# DECODER0_PVDEC_PIXEL register map
Vendor: Texas Instruments
Peripheral module from a debugger description file (folder J7ES).
Registers are 32-bit, read-write, reset 0x0 unless marked. A register's access mark holds for its fields unless they carry their own. Offsets are as the file gives them; lines under a group give offsets from that group; [hi:lo] are bit positions; {n}, {i} and the like mark numbered series; 'fields as' and 'values as' point back to an identical list; <NAME> marks a mode.

## DECODER0_PVDEC_PIXEL
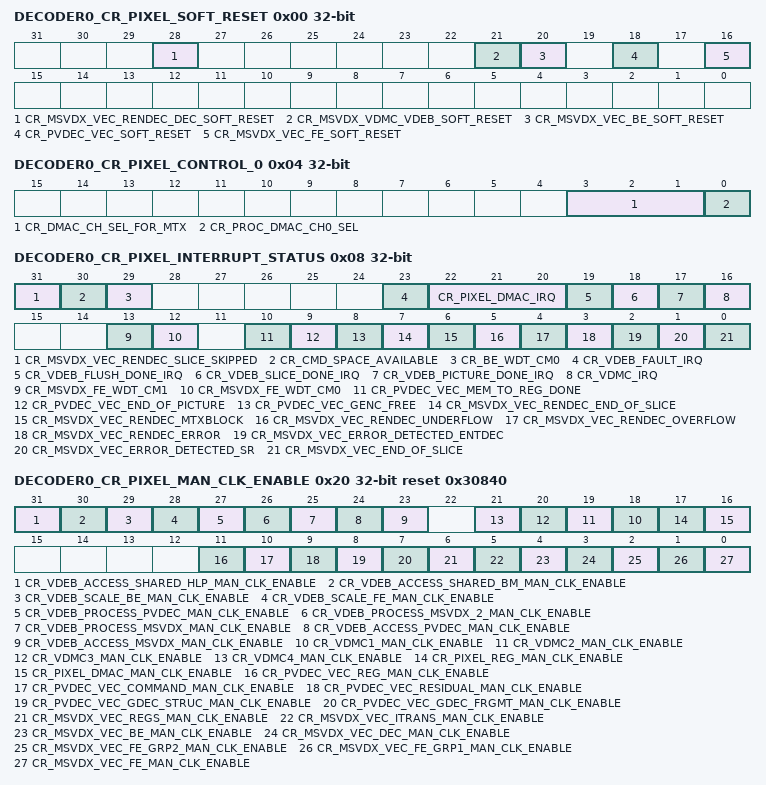
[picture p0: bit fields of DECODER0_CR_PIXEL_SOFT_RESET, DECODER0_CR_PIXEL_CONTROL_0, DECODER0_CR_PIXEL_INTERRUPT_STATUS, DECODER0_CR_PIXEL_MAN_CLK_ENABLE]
0x00 DECODER0_CR_PIXEL_SOFT_RESET
  [28] CR_MSVDX_VEC_RENDEC_DEC_SOFT_RESET — Writing '1' to this bit resets the rendec/decoder of MSVDX_VEC.
  [21] CR_MSVDX_VDMC_VDEB_SOFT_RESET — Performs a soft reset on the VDMC and VDEB modules.
  [20] CR_MSVDX_VEC_BE_SOFT_RESET — Writing '1' to this bit resets the back-end processing VEC modules that are:
  [18] CR_PVDEC_VEC_SOFT_RESET — Writing '1' to this bit resets the PVDEC_VEC, which includes
  [16] CR_MSVDX_VEC_FE_SOFT_RESET — Writing '1' to this bit resets the front-end logic of MSVDX_VEC, which includes:
0x04 DECODER0_CR_PIXEL_CONTROL_0
  [3:1] CR_DMAC_CH_SEL_FOR_MTX — Specifies which channel is used for Embedded processor RAM read/write.
  [0] CR_PROC_DMAC_CH0_SEL — This field controls how channel 0 of the DMA Controller in the 'Pixel Processing Pipe' selected by DMAC_PIPE_SELECT is used.
0x08 DECODER0_CR_PIXEL_INTERRUPT_STATUS
  [31] CR_MSVDX_VEC_RENDEC_SLICE_SKIPPED — Slice skip completed by vec/rendec/decoder.
  [30] CR_CMD_SPACE_AVAILABLE — Command buffer space available interrupt.
  [29] CR_BE_WDT_CM0 — CompareMatch0 condition encountered by back-end Watch Dog Timer.
  [23] CR_VDEB_FAULT_IRQ — VDEB detected a potential fault condition [Pulse generated at event, held by edge detection logic]
  [22:20] CR_PIXEL_DMAC_IRQ — The first two bits are directly correspond to DMA channels 0 and 1.
  [19] CR_VDEB_FLUSH_DONE_IRQ — Internal VDEB buffers have been flushed [Pulse generated at event, held by edge detection logic]
  [18] CR_VDEB_SLICE_DONE_IRQ — Deblock processing for slice is done [Pulse generated at event, held by edge detection logic]
  [17] CR_VDEB_PICTURE_DONE_IRQ — Deblock {VDMC for JPEG} processing for picture is done.
  [16] CR_VDMC_IRQ — Interrupt generated from VDMC [Level, OR of status bits in VDMC status register ANDed with corresponding enables]
  [13] CR_MSVDX_FE_WDT_CM1 — CompareMatch1 condition encountered by front-end Watch Dog Timer.
  [12] CR_MSVDX_FE_WDT_CM0 — CompareMatch0 condition encountered by front-end Watch Dog Timer.
  [10] CR_PVDEC_VEC_MEM_TO_REG_DONE — Indicates memory to register transfer is complete.
  [9] CR_PVDEC_VEC_END_OF_PICTURE — Indicates PVDEC VEC BE has finished decoding the current picture from the GENC buffer [VDMC/VDEB may still be processing the picture].
  [8] CR_PVDEC_VEC_GENC_FREE — Indicates GENC read buffer pointers have been updated to indicate the oldest data in the GENC buffer is no longer required.
  [7] CR_MSVDX_VEC_RENDEC_END_OF_SLICE — Notification of End Of Slice on the rendec stream.
  [6] CR_MSVDX_VEC_RENDEC_MTXBLOCK — Notification of MTX block data on the rendec stream.
  [5] CR_MSVDX_VEC_RENDEC_UNDERFLOW — The rendec stream in the allocated rendec buffer has become empty.
  [4] CR_MSVDX_VEC_RENDEC_OVERFLOW — The allocated rendec buffer has become full.
  [3] CR_MSVDX_VEC_RENDEC_ERROR — Error detected by vec/rendec block.
  [2] CR_MSVDX_VEC_ERROR_DETECTED_ENTDEC — Error detected by vec/entdec bit stream parser.
  [1] CR_MSVDX_VEC_ERROR_DETECTED_SR — Error detected on the bit stream by shift register.
  [0] CR_MSVDX_VEC_END_OF_SLICE — End of slice status bit for the VEC front-end parser.
0x0C DECODER0_CR_PIXEL_INTERRUPT_CLEAR
  [31:0] CR_PIXEL_IRQ_CLEAR — The value read from PIXEL_INTERRUPT_STATUS register is based on 'input source' ORed with 'rising edge detection' logic.
0x10 DECODER0_CR_PIXEL_HOST_INTERRUPT_ENABLE
  [31:0] CR_HOST_IRQ_ENABLE — Enables interrupts which will become a HOST_PIXEL_PIPE_IRQ in the PVDEC_CORE registers.
0x14 DECODER0_CR_PIXEL_PROC1_INTERRUPT_ENABLE
  [31:0] CR_PROC1_IRQ_ENABLE — Enables interrupts which will become a PROC1_PIXEL_PIPE_IRQ in the PVDEC_CORE registers.
0x18 DECODER0_CR_PIXEL_PROC2_INTERRUPT_ENABLE
  [31:0] CR_PROC2_IRQ_ENABLE — Enables interrupts which will become a PROC2_PIXEL_PIPE_IRQ in the PVDEC_CORE registers.
0x20 DECODER0_CR_PIXEL_MAN_CLK_ENABLE reset 0x30840
  [31] CR_VDEB_ACCESS_SHARED_HLP_MAN_CLK_ENABLE — Controls the clock for the shared high level parameter store of the deblocker[if this bit is set, clock is active, and AUTO_CLK_ENABLE is ignored]
  [30] CR_VDEB_ACCESS_SHARED_BM_MAN_CLK_ENABLE — Controls the clock for the shared block memory of the deblocker[if this bit is set, clock is active, and AUTO_CLK_ENABLE is ignored]
  [29] CR_VDEB_SCALE_BE_MAN_CLK_ENABLE — Controls the clock for the back-end logic of the deblocker scaler processing [if this bit is set, clock is active, and AUTO_CLK_ENABLE is ignored]
  [28] CR_VDEB_SCALE_FE_MAN_CLK_ENABLE — Controls the clock for the front-end logic of the deblocker scaler processing [if this bit is set, clock is active, and AUTO_CLK_ENABLE is ignored]
  [27] CR_VDEB_PROCESS_PVDEC_MAN_CLK_ENABLE — Controls the clock for PVDEC path of the deblocker processing [if this bit is set, clock is active, and AUTO_CLK_ENABLE is ignored]
  [26] CR_VDEB_PROCESS_MSVDX_2_MAN_CLK_ENABLE — Controls the clock for MSVDX path domain 2 of the deblocker processing [if this bit is set, clock is active, and AUTO_CLK_ENABLE is ignored]
  [25] CR_VDEB_PROCESS_MSVDX_MAN_CLK_ENABLE — Controls the clock for MSVDX path domain1 of the deblocker processing [if this bit is set, clock is active, and AUTO_CLK_ENABLE is ignored]
  [24] CR_VDEB_ACCESS_PVDEC_MAN_CLK_ENABLE — Controls the clock for PVDEC path of the deblocker access [if this bit is set, clock is active, and AUTO_CLK_ENABLE is ignored]
  [23] CR_VDEB_ACCESS_MSVDX_MAN_CLK_ENABLE — Controls the clock for MSVDX path of the deblocker access [if this bit is set, clock is active, and AUTO_CLK_ENABLE is ignored]
  [n+17] CR_VDMC{n}_MAN_CLK_ENABLE (n=1..4) — Controls the clock for the domain {n} in the motion compensation block [if this bit is set, clock is active, and AUTO_CLK_ENABLE is ignored]
  [17] CR_PIXEL_REG_MAN_CLK_ENABLE — Controls the clock for the Pixel pipe registers [if this bit is set, clock is active, and AUTO_CLK_ENABLE is ignored]
  [16] CR_PIXEL_DMAC_MAN_CLK_ENABLE — Controls the clock for the Pixel processing DMA Controller [if this bit is set, clock is active, and AUTO_CLK_ENABLE is ignored]
  [11] CR_PVDEC_VEC_REG_MAN_CLK_ENABLE — Controls the clock for the register bankis of PVDEC_VEC_BE [if this bit is set, clock is active, and AUTO_CLK_ENABLE is ignored]
  [10] CR_PVDEC_VEC_COMMAND_MAN_CLK_ENABLE — Controls the clock for the command generation logic of PVDEC_VEC_BE [if this bit is set, clock is active, and AUTO_CLK_ENABLE is ignored]
  [9] CR_PVDEC_VEC_RESIDUAL_MAN_CLK_ENABLE — Controls the clock for the residual decode logic of PVDEC_VEC_BE [if this bit is set, clock is active, and AUTO_CLK_ENABLE is ignored]
  [8] CR_PVDEC_VEC_GDEC_STRUC_MAN_CLK_ENABLE — Controls the clock for the GENC decoder structure read logic of PVDEC_VEC_BE [if this bit is set, clock is active, and AUTO_CLK_ENABLE is ignored]
  [7] CR_PVDEC_VEC_GDEC_FRGMT_MAN_CLK_ENABLE — Controls the clock for the GENC decoder fragment read logic of PVDEC_VEC_BE [if this bit is set, clock is active, and AUTO_CLK_ENABLE is ignored]
  [6] CR_MSVDX_VEC_REGS_MAN_CLK_ENABLE — Controls the clock for VEC's register logic [if this bit is set, clock is active, and AUTO_CLK_ENABLE is ignored]
  [5] CR_MSVDX_VEC_ITRANS_MAN_CLK_ENABLE — Controls the clock for the MSVDX inverse transform block [if this bit is set, clock is active, and AUTO_CLK_ENABLE is ignored]
  [4] CR_MSVDX_VEC_BE_MAN_CLK_ENABLE — Controls the clock for the back-end logic of MSVDX_VEC/ENTDEC [if this bit is set, clock is active, and AUTO_CLK_ENABLE is ignored].
  [3] CR_MSVDX_VEC_DEC_MAN_CLK_ENABLE — Controls the clock for the rendec decoder logic of MSVDX_VEC/ENTDEC [if this bit is set, clock is active, and AUTO_CLK_ENABLE is ignored].
  [2] CR_MSVDX_VEC_FE_GRP2_MAN_CLK_ENABLE — Controls the clock for the front-end logic for codec group 2 in MSVDX_VEC/ENTDEC [if this bit is set, clock is active, and AUTO_CLK_ENABLE is ignored]
  [1] CR_MSVDX_VEC_FE_GRP1_MAN_CLK_ENABLE — Controls the clock for the front-end logic for codec group 1 in MSVDX_VEC/ENTDEC [if this bit is set, clock is active, and AUTO_CLK_ENABLE is ignored]
  [0] CR_MSVDX_VEC_FE_MAN_CLK_ENABLE — Controls the clock for the front-end common logic MSVDX_VEC/ENTDEC [if this bit is set, clock is active, and AUTO_CLK_ENABLE is ignored]
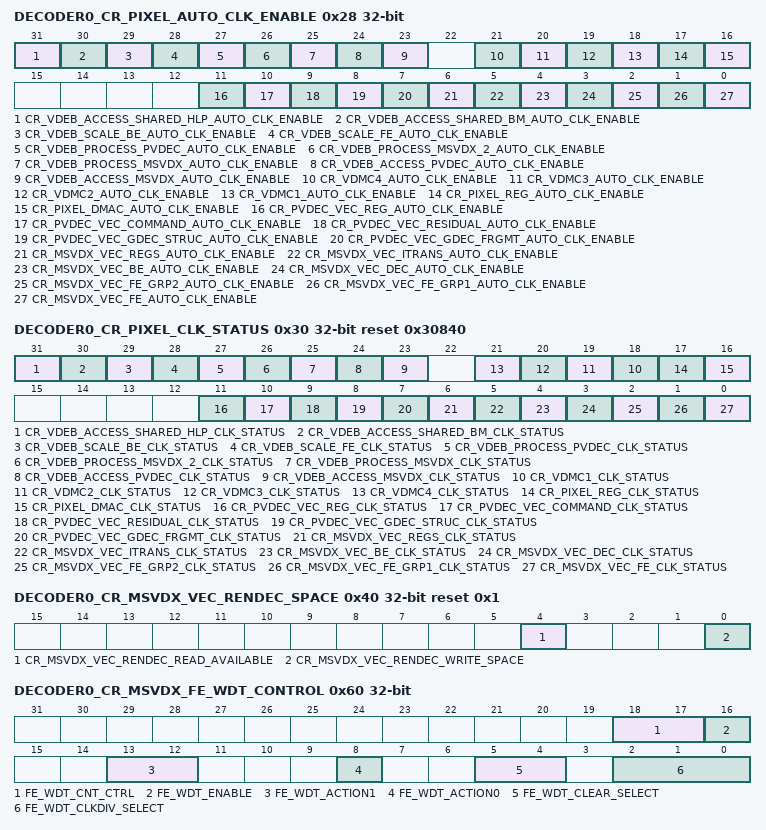
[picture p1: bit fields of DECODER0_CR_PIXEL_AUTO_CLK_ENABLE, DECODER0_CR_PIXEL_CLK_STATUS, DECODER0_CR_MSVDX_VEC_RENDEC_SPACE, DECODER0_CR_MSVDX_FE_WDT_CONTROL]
0x28 DECODER0_CR_PIXEL_AUTO_CLK_ENABLE
  [31] CR_VDEB_ACCESS_SHARED_HLP_AUTO_CLK_ENABLE — Controls automatic clock gating for the shared high level parameter store of the deblocker[if MAN_CLK_ENABLE is clear and AUTO_CLK_ENABLE is set, clock will stop if VDEB shared HLP is idle]
  [30] CR_VDEB_ACCESS_SHARED_BM_AUTO_CLK_ENABLE — Controls automatic clock gating for the shared block memory of the deblocker[if MAN_CLK_ENABLE is clear and AUTO_CLK_ENABLE is set, clock will stop if VDEB shared BM is idle]
  [29] CR_VDEB_SCALE_BE_AUTO_CLK_ENABLE — Controls automatic clock gating for the back-end logic of the deblocker scaler processing [if MAN_CLK_ENABLE is clear and AUTO_CLK_ENABLE is set, clock will stop if VDEB scale BE is idle]
  [28] CR_VDEB_SCALE_FE_AUTO_CLK_ENABLE — Controls automatic clock gating for the front-end logic of the deblocker scaler processing [if MAN_CLK_ENABLE is clear and AUTO_CLK_ENABLE is set, clock will stop if VDEB scale FE is idle]
  [27] CR_VDEB_PROCESS_PVDEC_AUTO_CLK_ENABLE — Controls automatic clock gating for PVDEC path of the deblocker processing [if MAN_CLK_ENABLE is clear and AUTO_CLK_ENABLE is set, clock will stop if PVDEC domain process is idle]
  [26] CR_VDEB_PROCESS_MSVDX_2_AUTO_CLK_ENABLE — Controls automatic clock gating for MSVDX path domain 2 of the deblocker processing [if MAN_CLK_ENABLE is clear and AUTO_CLK_ENABLE is set, clock will stop if MSVDX domain 2 processing is idle]
  [25] CR_VDEB_PROCESS_MSVDX_AUTO_CLK_ENABLE — Controls automatic clock gating for MSVDX path domain1 of the deblocker processing [if MAN_CLK_ENABLE is clear and AUTO_CLK_ENABLE is set, clock will stop if MSVDX domain processing is idle]
  [24] CR_VDEB_ACCESS_PVDEC_AUTO_CLK_ENABLE — Controls automatic clock gating for PVDEC path of the deblocker access [if MAN_CLK_ENABLE is clear and AUTO_CLK_ENABLE is set, clock will stop if PVDEC domain access is idle]
  [23] CR_VDEB_ACCESS_MSVDX_AUTO_CLK_ENABLE — Controls automatic clock gating for MSVDX path of the deblocker access [if MAN_CLK_ENABLE is clear and AUTO_CLK_ENABLE is set, clock will stop if MSVDX domain access is idle]
  [21] CR_VDMC4_AUTO_CLK_ENABLE — Controls automatic clock gating for the domain 4 in the motion compensation block [if MAN_CLK_ENABLE is clear and AUTO_CLK_ENABLE is set, clock will stop if VDMC domain 2 is idle]
  [20] CR_VDMC3_AUTO_CLK_ENABLE — Controls automatic clock gating for the domain 3 in the motion compensation block [if MAN_CLK_ENABLE is clear and AUTO_CLK_ENABLE is set, clock will stop if VDMC domain 1 is idle]
  [19] CR_VDMC2_AUTO_CLK_ENABLE — Controls automatic clock gating for the domain 2 in the motion compensation block [if MAN_CLK_ENABLE is clear and AUTO_CLK_ENABLE is set, clock will stop if VDMC domain 1 is idle]
  [18] CR_VDMC1_AUTO_CLK_ENABLE — Controls automatic clock gating for the domain 1 in the motion compensation block [if MAN_CLK_ENABLE is clear and AUTO_CLK_ENABLE is set, clock will stop if VDMC domain 1 is idle]
  [17] CR_PIXEL_REG_AUTO_CLK_ENABLE — Controls automatic clock gating for the Pixel Processing registers [if MAN_CLK_ENABLE is clear and AUTO_CLK_ENABLE is set, clock will stop if Pixel Processing register access is idle]
  [16] CR_PIXEL_DMAC_AUTO_CLK_ENABLE — Controls automatic clock gating for the Pixel processing DMA Controller [if MAN_CLK_ENABLE is clear and AUTO_CLK_ENABLE is set, clock will stop if DMA controller is idle]
  [11] CR_PVDEC_VEC_REG_AUTO_CLK_ENABLE — Controls automatic clock gating for the register banks of PVDEC_VEC_BE [if MAN_CLK_ENABLE is clear and AUTO_CLK_ENABLE is set, clock will stop if Pixel Processing register access is idle]
  [10] CR_PVDEC_VEC_COMMAND_AUTO_CLK_ENABLE — Controls automatic clock gating for the command generation logic of PVDEC_VEC_BE [if MAN_CLK_ENABLE is clear and AUTO_CLK_ENABLE is set, clock will stop if command generation is idle]
  [9] CR_PVDEC_VEC_RESIDUAL_AUTO_CLK_ENABLE — Controls automatic clock gating for the residual decode logic of PVDEC_VEC_BE [if MAN_CLK_ENABLE is clear and AUTO_CLK_ENABLE is set, clock will stop if residual decode is idle]
  [8] CR_PVDEC_VEC_GDEC_STRUC_AUTO_CLK_ENABLE — Controls automatic clock gating for the GENC decoder structure read logic of PVDEC_VEC_BE [if MAN_CLK_ENABLE is clear and AUTO_CLK_ENABLE is set, clock will stop if GENC decoder is idle]
  [7] CR_PVDEC_VEC_GDEC_FRGMT_AUTO_CLK_ENABLE — Controls automatic clock gating for the GENC decoder fragment read logic of PVDEC_VEC_BE [if MAN_CLK_ENABLE is clear and AUTO_CLK_ENABLE is set, clock will stop if GENC decoder is idle]
  [6] CR_MSVDX_VEC_REGS_AUTO_CLK_ENABLE — Controls automatic clock gating for VEC's register logic [if MAN_CLK_ENABLE is clear and AUTO_CLK_ENABLE is set, clock will stop if VEC register access is idle]
  [5] CR_MSVDX_VEC_ITRANS_AUTO_CLK_ENABLE — Controls automatic clock gating for the MSVDX inverse transform block [if MAN_CLK_ENABLE is clear and AUTO_CLK_ENABLE is set, clock will stop if MSVDX inverse transform is idle]
  [4] CR_MSVDX_VEC_BE_AUTO_CLK_ENABLE — Controls automatic clock gating for the back-end logic of MSVDX_VEC/ENTDEC [if MAN_CLK_ENABLE is clear and AUTO_CLK_ENABLE is set, clock will stop if MSVDX_VEC back-end is idle]
  [3] CR_MSVDX_VEC_DEC_AUTO_CLK_ENABLE — Controls automatic clock gating for the rendec decoder logic of MSVDX_VEC/ENTDEC [if MAN_CLK_ENABLE is clear and AUTO_CLK_ENABLE is set, clock will stop if MSVDX rendec decode is idle]
  [2] CR_MSVDX_VEC_FE_GRP2_AUTO_CLK_ENABLE — Controls automatic clock gating for the front-end logic for codec group 2 in MSVDX_VEC/ENTDEC [if MAN_CLK_ENABLE is clear and AUTO_CLK_ENABLE is set, clock will stop if MSVDX_VEC front-end group 2 is idle]
  [1] CR_MSVDX_VEC_FE_GRP1_AUTO_CLK_ENABLE — Controls automatic clock gating for the front-end logic for codec group 1 in MSVDX_VEC/ENTDEC [if MAN_CLK_ENABLE is clear and AUTO_CLK_ENABLE is set, clock will stop if MSVDX_VEC front-end group 1 is idle]
  [0] CR_MSVDX_VEC_FE_AUTO_CLK_ENABLE — Controls automatic clock gating for the front-end common logic in MSVDX_VEC/ENTDEC [if MAN_CLK_ENABLE is clear and AUTO_CLK_ENABLE is set, clock will stop if MSVDX_VEC front-end group 1 is idle]
0x30 DECODER0_CR_PIXEL_CLK_STATUS ro reset 0x30840
  [31] CR_VDEB_ACCESS_SHARED_HLP_CLK_STATUS — Indicates if the clock is enabled to the shared high level parameter store of the deblocker
  [30] CR_VDEB_ACCESS_SHARED_BM_CLK_STATUS — Indicates if the clock is enabled to the shared block memory of the deblocker
  [29] CR_VDEB_SCALE_BE_CLK_STATUS — Indicates if the clock is enabled to the back-end logic of the deblocker scaler processing
  [28] CR_VDEB_SCALE_FE_CLK_STATUS — Indicates if the clock is enabled to the front-end logic of the deblocker scaler processing
  [27] CR_VDEB_PROCESS_PVDEC_CLK_STATUS — Indicates if the clock is enabled to the PVDEC path of the deblocker processing
  [26] CR_VDEB_PROCESS_MSVDX_2_CLK_STATUS — Indicates if the clock is enabled to the MSVDX path domain 2 of the deblocker processing
  [25] CR_VDEB_PROCESS_MSVDX_CLK_STATUS — Indicates if the clock is enabled to the MSVDX path domain1 of the deblocker processing
  [24] CR_VDEB_ACCESS_PVDEC_CLK_STATUS — Indicates if the clock is enabled to the PVDEC path of the deblocker access
  [23] CR_VDEB_ACCESS_MSVDX_CLK_STATUS — Indicates if the clock is enabled to the MSVDX path of the deblocker access
  [n+17] CR_VDMC{n}_CLK_STATUS (n=1..4) — Indicates if the clock is enabled to the domain {n} in the motion compensation block
  [17] CR_PIXEL_REG_CLK_STATUS — Indicates if the clock is enabled to the Pixel Processing registers
  [16] CR_PIXEL_DMAC_CLK_STATUS — Indicates if the clock is enabled to the Pixel processing DMA Controller
  [11] CR_PVDEC_VEC_REG_CLK_STATUS — Indicates if the clock is enabled to the register banks of PVDEC_VEC_BE
  [10] CR_PVDEC_VEC_COMMAND_CLK_STATUS — Indicates if the clock is enabled to the command generation logic of PVDEC_VEC_BE
  [9] CR_PVDEC_VEC_RESIDUAL_CLK_STATUS — Indicates if the clock is enabled to the residual decode logic of PVDEC_VEC_BE
  [8] CR_PVDEC_VEC_GDEC_STRUC_CLK_STATUS — Indicates if the clock is enabled to the vec genc_dec structure read logic of PVDEC_VEC_BE
  [7] CR_PVDEC_VEC_GDEC_FRGMT_CLK_STATUS — Indicates if the clock is enabled to the vec genc_dec fragment read logic of PVDEC_VEC_BE
  [6] CR_MSVDX_VEC_REGS_CLK_STATUS — Indicates if the clock is enabled to VEC's register logic
  [5] CR_MSVDX_VEC_ITRANS_CLK_STATUS — Indicates if the clock is enabled to the MSVDX inverse transform block
  [4] CR_MSVDX_VEC_BE_CLK_STATUS — Indicates if the clock is enabled to the back-end logic of MSVDX_VEC/ENTDEC
  [3] CR_MSVDX_VEC_DEC_CLK_STATUS — Indicates if the clock is enabled to the rendec decoder logic of MSVDX_VEC/ENTDEC
  [2] CR_MSVDX_VEC_FE_GRP2_CLK_STATUS — Indicates if the clock is enabled to the front-end logic for codec group 2 in MSVDX_VEC/ENTDEC
  [1] CR_MSVDX_VEC_FE_GRP1_CLK_STATUS — Indicates if the clock is enabled to the front-end logic for codec group 1 in MSVDX_VEC/ENTDEC
  [0] CR_MSVDX_VEC_FE_CLK_STATUS — Indicates if the clock is enabled to the front-end common logic in MSVDX_VEC/ENTDEC
0x40 DECODER0_CR_MSVDX_VEC_RENDEC_SPACE ro reset 0x1
  [4] CR_MSVDX_VEC_RENDEC_READ_AVAILABLE — Indicates if master can read 1 word from rendec without stalling
  [0] CR_MSVDX_VEC_RENDEC_WRITE_SPACE — Indicates if master can write 1 word to rendec without stalling
0x50 DECODER0_CR_PIXEL_DMAC_STREAM_INTERRUPT_ENABLE reset 0x1
  [3:0] CR_DMAC_STREAM_INTERRUPT_ENABLE — The value in this register is ANDed with the value in DMAC_STREAM_STATUS, and the resulting
0x54 DECODER0_CR_PIXEL_DMAC_STREAM_STATUS ro
  [3:0] CR_PIXEL_DMAC_STREAM_STATUS — Bit 0 of this register corresponds to DMAC channel 2 interrupt, which is associated with stream 0.
0x60 DECODER0_CR_MSVDX_FE_WDT_CONTROL
  [18:17] FE_WDT_CNT_CTRL — The increment of FE_WDT counter can be controlled depending on the settings below.
  [16] FE_WDT_ENABLE — Front-end Watch Dog Timer enable
  [13:12] FE_WDT_ACTION1 — Watch Dog Timer action upon WDT_COMPAREMATCH1
  [8] FE_WDT_ACTION0 — Watch Dog Timer action upon WDT_COMPAREMATCH0.
  [5:4] FE_WDT_CLEAR_SELECT — Watch Dog Timer clear select
  [2:0] FE_WDT_CLKDIV_SELECT — Watch Dog Timer clock select
0x64 DECODER0_CR_MSVDX_FE_WDTIMER
  [15:0] FE_WDT_COUNTER — Watch Dog Timer counter value.
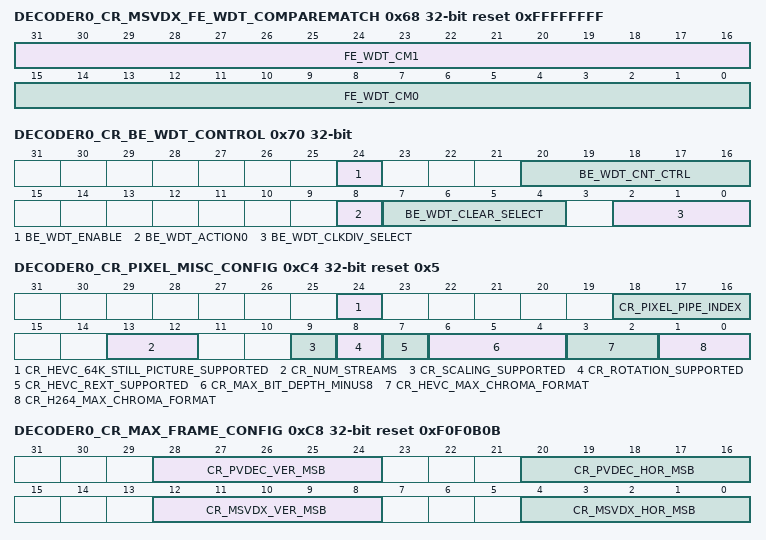
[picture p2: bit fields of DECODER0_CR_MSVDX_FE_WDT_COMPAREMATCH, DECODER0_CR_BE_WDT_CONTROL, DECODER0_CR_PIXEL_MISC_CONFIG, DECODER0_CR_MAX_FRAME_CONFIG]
0x68 DECODER0_CR_MSVDX_FE_WDT_COMPAREMATCH reset 0xFFFFFFFF
  [31:16] FE_WDT_CM1 — Watch Dog Timer compare-match register.
  [15:0] FE_WDT_CM0 — Watch Dog Timer compare-match register.
0x70 DECODER0_CR_BE_WDT_CONTROL
  [24] BE_WDT_ENABLE — Back-end Watch Dog Timer enable
  [20:16] BE_WDT_CNT_CTRL — The increment of BE_WDT counter can be controlled depending on the settings below.
  [8] BE_WDT_ACTION0 — Watch Dog Timer action upon WDT_COMPAREMATCH0
  [7:4] BE_WDT_CLEAR_SELECT — Watch Dog Timer clear select
  [2:0] BE_WDT_CLKDIV_SELECT — Watch Dog Timer clock select
0x74 DECODER0_CR_BE_WDTIMER
  [15:0] BE_WDT_COUNTER — Watch Dog Timer counter value.
0x78 DECODER0_CR_BE_WDT_COMPAREMATCH reset 0xFFFF
  [15:0] BE_WDT_CM0 — Watch Dog Timer compare-match register.
0x80 DECODER0_CR_PVDEC_COMMAND_SPACE ro reset 0x80
  [31:0] CR_PVDEC_CMD_BUFFER_SPACE — Indicates the number of commands which can be sent to command bus without stalling master
0x84 DECODER0_CR_PVDEC_COMMAND_BUFFER_CTRL reset 0x80
  [7:0] CR_PVDEC_CMD_BUFFER_THRESHOLD — When there is more space available in the command buffer than the value specified by this register, the transient is notified to COMMAND_SPACE_AVAILABLE bit of the interrupt status register.
0x90 DECODER0_CR_MEM_SECURITY_DMAC
  [15:0] CR_MEM_SECURITY_DMAC_CTRL — MEM_TAG_ID is compared to the corresponding bit position of this field to determine whether to flag the Security or not
0x94 DECODER0_CR_MEM_SECURITY_VEC_0
  [31:0] CR_MEM_SECURITY_VEC_CTRL_0 — MEM_TAG_ID is compared to the corresponding bit position of the concatenated field [MEM_SECURITY_VEC_CTRL_1 &amp; MEM_SECURITY_VEC_CTRL_0] to determine whether to flag the Security or not
0x98 DECODER0_CR_MEM_SECURITY_VEC_1
  [31:0] CR_MEM_SECURITY_VEC_CTRL_1 — Refer to MEM_SECURITY_VEC_0 register description
0x9C DECODER0_CR_MEM_SECURITY_VDMC_0
  [15:0] CR_MEM_SECURITY_VDMC_CTRL_0 — MEM_TAG_ID is compared to the corresponding bit position of this field to determine whether to flag the Security or not
0xA4 DECODER0_CR_MEM_SECURITY_VDEB_0
  [31:0] CR_MEM_SECURITY_VDEB_CTRL_0 — MEM_TAG_ID is compared to the corresponding bit position of this field to determine whether to flag the Security or not
0xAC DECODER0_CR_MEM_SECURITY_SCALE_0
  [0] CR_MEM_SECURITY_SCALE_CTRL_0 — MEM_TAG_ID is compared to the corresponding bit position of this field to determine whether to flag the Security or not
0xC0 DECODER0_CR_PIXEL_PIPE_CONFIG ro
  [31:0] CR_PIXEL_PIPE_CONFIG — This field indicates which CODECs are supported in a Pixel Processing Pipe [where different pipes can be configured to support a different range of codecs].
0xC4 DECODER0_CR_PIXEL_MISC_CONFIG ro reset 0x5
  [24] CR_HEVC_64K_STILL_PICTURE_SUPPORTED — This field indicates if the maximum picture size supported for HEVC still picture profile is 64k wide and/or 64k high
  [18:16] CR_PIXEL_PIPE_INDEX — This field indicates pixel processing pipe index [starting at 1]
  [13:12] CR_NUM_STREAMS — This field indicates 'Number streams-1' supported by Pixel pipe DMAC and shift register [where the number of DMAC channels = 3+NUM_STREAMS]
  [9] CR_SCALING_SUPPORTED — This field indicates if scaling of decoded frames is supported
  [8] CR_ROTATION_SUPPORTED — This field indicates if rotation of decoded frames is supported
  [7] CR_HEVC_REXT_SUPPORTED — This field indicates if HEVC RExt is fully supported
  [6:4] CR_MAX_BIT_DEPTH_MINUS8 — This field +8 indicates the maximum bit depth supported by the pipe [where 0 corresponds to
  [3:2] CR_HEVC_MAX_CHROMA_FORMAT — This field indicates the maximum chroma format supported by the pipe in HEVC mode
  [1:0] CR_H264_MAX_CHROMA_FORMAT — This field indicates the maximum chroma format supported by the pipe in H264 mode
0xC8 DECODER0_CR_MAX_FRAME_CONFIG ro reset 0xF0F0B0B
  [28:24] CR_PVDEC_VER_MSB — This field indicates the maximum frame height supported in the PVDEC pipeline, where the maximum frame height is '2 shifted left by PVDEC_VER_MSB'
  [20:16] CR_PVDEC_HOR_MSB — This field indicates the maximum frame width supported in the PVDEC pipeline, where the maximum frame width is '2 shifted left by PVDEC_HOR_MSB'
  [12:8] CR_MSVDX_VER_MSB — This field indicates the maximum frame height supported in the MSVDX pipeline, where the maximum frame height is '2 shifted left by MSVDX_VER_MSB'
  [4:0] CR_MSVDX_HOR_MSB — This field indicates the maximum frame width supported in the MSVDX pipeline, where the maximum frame width is '2 shifted left by MSVDX_HOR_MSB'
0xE0 DECODER0_CR_VDMC_VDEB_COMMAND_SIGNATURE — This is a signature of address and data of commands sent to VDMC/VDEB, which is the combination of macroblock level commands, slice level commands, and any other high level commands.
  [31:0] CR_VDMC_VDEB_COMMAND_SIGNATURE — Signature of the address and data of all commands sent to VDMC and VDEB [at the output stage of the Pixel pipeline cross-bar], except any commands specifying a base address have the data value into the signature forced to 0.
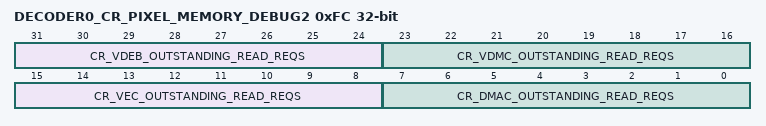
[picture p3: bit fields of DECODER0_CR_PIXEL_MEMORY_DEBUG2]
0xFC DECODER0_CR_PIXEL_MEMORY_DEBUG2 ro
  [31:24] CR_VDEB_OUTSTANDING_READ_REQS — Indicates the number of outstanding read requests for VDEB.
  [23:16] CR_VDMC_OUTSTANDING_READ_REQS — Indicates the number of outstanding read requests for VDMC.
  [15:8] CR_VEC_OUTSTANDING_READ_REQS — Indicates the number of outstanding read requests for VEC.
  [7:0] CR_DMAC_OUTSTANDING_READ_REQS — Indicates the number of outstanding read requests for DMAC.
